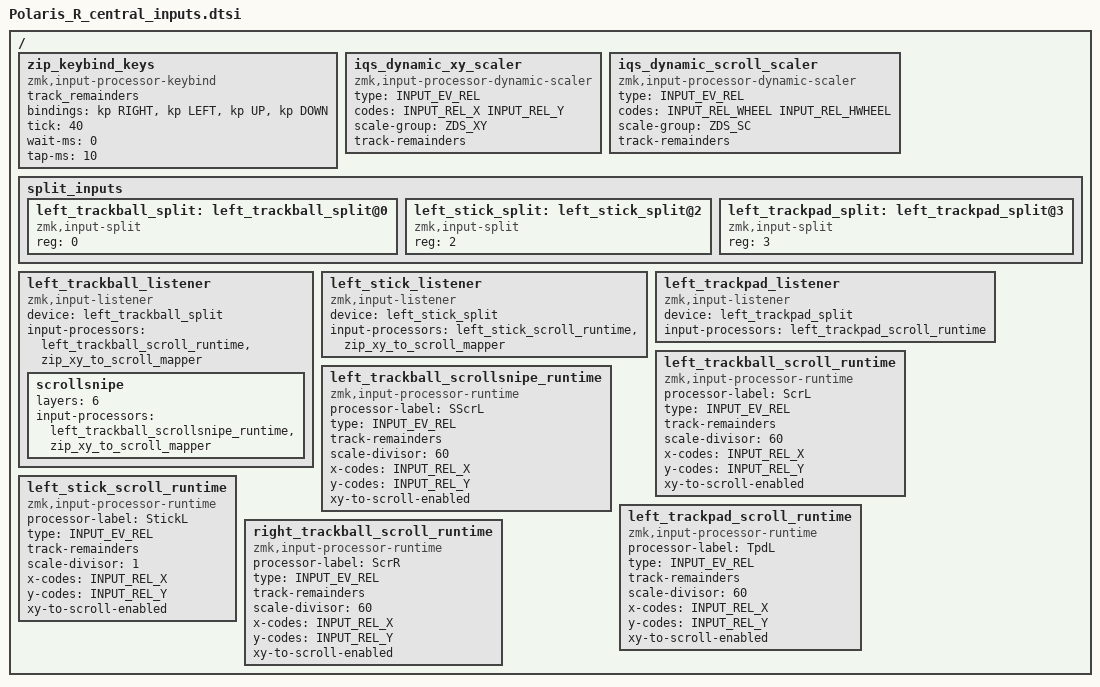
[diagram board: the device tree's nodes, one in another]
#include <input/processors.dtsi>
#include <dt-bindings/zmk/input_transform.h>
#include <dt-bindings/zmk/zip_dynamic_scale.h>
#include <zephyr/dt-bindings/input/input-event-codes.h>
#include <dt-bindings/zmk/keys.h>
#include <input/processors/runtime-input-processor.dtsi>

/ {
    zip_keybind_keys: zip_keybind_keys {
        compatible = "zmk,input-processor-keybind";
        #input-processor-cells = <0>;
        track_remainders;
        bindings = <&kp RIGHT>,
                   <&kp LEFT>,
                   <&kp UP>,
                   <&kp DOWN>;
        tick = <40>;
        wait-ms = <0>;
        tap-ms = <10>;
    };

    iqs_dynamic_xy_scaler: iqs_dynamic_xy_scaler {
        compatible = "zmk,input-processor-dynamic-scaler";
        #input-processor-cells = <0>;
        type = <INPUT_EV_REL>;
        codes = <INPUT_REL_X INPUT_REL_Y>;
        scale-group = <ZDS_XY>;
        track-remainders;
    };

    iqs_dynamic_scroll_scaler: iqs_dynamic_scroll_scaler {
        compatible = "zmk,input-processor-dynamic-scaler";
        #input-processor-cells = <0>;
        type = <INPUT_EV_REL>;
        codes = <INPUT_REL_WHEEL INPUT_REL_HWHEEL>;
        scale-group = <ZDS_SC>;
        track-remainders;
    };

    split_inputs {
        #address-cells = <1>;
        #size-cells = <0>;

        left_trackball_split: left_trackball_split@0 {
            compatible = "zmk,input-split";
            status = "okay";
            reg = <0>;
        };

        left_stick_split: left_stick_split@2 {
            compatible = "zmk,input-split";
            status = "okay";
            reg = <2>;
        };

        left_trackpad_split: left_trackpad_split@3 {
            compatible = "zmk,input-split";
            status = "okay";
            reg = <3>;
        };
    };

    left_trackball_listener: left_trackball_listener {
        compatible = "zmk,input-listener";
        status = "okay";
        device = <&left_trackball_split>;
        input-processors = <&left_trackball_scroll_runtime>,
                           <&zip_xy_to_scroll_mapper>;

        scrollsnipe {
            layers = <6>;
            input-processors = <&left_trackball_scrollsnipe_runtime>,
                               <&zip_xy_to_scroll_mapper>;
        };
    };

    left_stick_listener: left_stick_listener {
        compatible = "zmk,input-listener";
        status = "okay";
        device = <&left_stick_split>;
        input-processors = <&left_stick_scroll_runtime>,
                           <&zip_xy_to_scroll_mapper>;
    };

    left_trackpad_listener: left_trackpad_listener {
        compatible = "zmk,input-listener";
        status = "okay";
        device = <&left_trackpad_split>;
        input-processors = <&left_trackpad_scroll_runtime>;
    };

    left_trackball_scroll_runtime: left_trackball_scroll_runtime {
        compatible = "zmk,input-processor-runtime";
        processor-label = "ScrL";
        type = <INPUT_EV_REL>;
        track-remainders;
        scale-divisor = <60>;
        #input-processor-cells = <0>;
    };

    left_trackball_scrollsnipe_runtime: left_trackball_scrollsnipe_runtime {
        compatible = "zmk,input-processor-runtime";
        processor-label = "SScrL";
        type = <INPUT_EV_REL>;
        track-remainders;
        scale-divisor = <60>;
        #input-processor-cells = <0>;
    };

    left_stick_scroll_runtime: left_stick_scroll_runtime {
        compatible = "zmk,input-processor-runtime";
        processor-label = "StickL";
        type = <INPUT_EV_REL>;
        track-remainders;
        scale-divisor = <1>;
        #input-processor-cells = <0>;
    };

    left_trackpad_scroll_runtime: left_trackpad_scroll_runtime {
        compatible = "zmk,input-processor-runtime";
        processor-label = "TpdL";
        type = <INPUT_EV_REL>;
        track-remainders;
        scale-divisor = <60>;
        #input-processor-cells = <0>;
    };

    right_trackball_scroll_runtime: right_trackball_scroll_runtime {
        compatible = "zmk,input-processor-runtime";
        processor-label = "ScrR";
        type = <INPUT_EV_REL>;
        track-remainders;
        scale-divisor = <60>;
        #input-processor-cells = <0>;
    };
};

&left_trackball_scroll_runtime {
    x-codes = <INPUT_REL_X>;
    y-codes = <INPUT_REL_Y>;
    xy-to-scroll-enabled;
};

&left_trackball_scrollsnipe_runtime {
    x-codes = <INPUT_REL_X>;
    y-codes = <INPUT_REL_Y>;
    xy-to-scroll-enabled;
};

&left_stick_scroll_runtime {
    x-codes = <INPUT_REL_X>;
    y-codes = <INPUT_REL_Y>;
    xy-to-scroll-enabled;
};

&left_trackpad_scroll_runtime {
    x-codes = <INPUT_REL_X>;
    y-codes = <INPUT_REL_Y>;
    xy-to-scroll-enabled;
};

&right_trackball_scroll_runtime {
    x-codes = <INPUT_REL_X>;
    y-codes = <INPUT_REL_Y>;
    xy-to-scroll-enabled;
};
